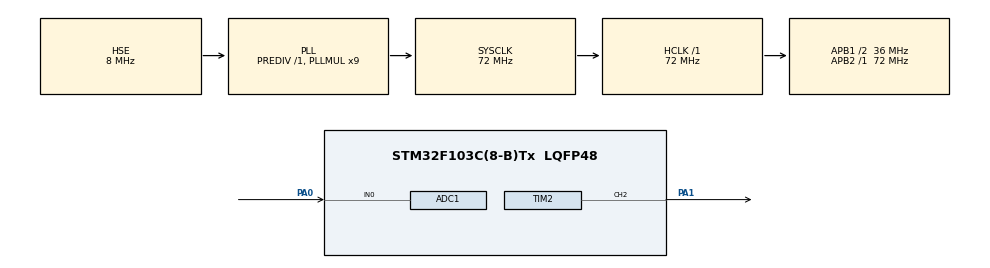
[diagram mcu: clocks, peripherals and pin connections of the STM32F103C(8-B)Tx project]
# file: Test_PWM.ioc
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ADC1.Channel-3\#ChannelRegularConversion=ADC_CHANNEL_0
ADC1.ContinuousConvMode=ENABLE
ADC1.NbrOfConversionFlag=1
ADC1.Rank-3\#ChannelRegularConversion=1
ADC1.SamplingTime-3\#ChannelRegularConversion=ADC_SAMPLETIME_1CYCLE_5
ADC1.master=1
FREERTOS.Tasks01=defaultTask,24,128,StartDefaultTask,Default,NULL,Dynamic,NULL,NULL;my_PhotoResisto,8,200,Start_PhotoResistor_Task,Default,NULL,Static,my_PhotoResistoBuffer,my_PhotoResistoControlBlock
Mcu.Family=STM32F1
Mcu.Name=STM32F103C(8-B)Tx
Mcu.Package=LQFP48
NVIC.PriorityGroup=NVIC_PRIORITYGROUP_4
NVIC.TIM4_IRQn=true\:0\:0\:false\:false\:true\:false\:false\:true
NVIC.TimeBase=TIM4_IRQn
NVIC.TimeBaseIP=TIM4
PA0-WKUP.Signal=ADCx_IN0
PA1.Signal=S_TIM2_CH2
PA13.Mode=Trace_Asynchronous_SW
PA13.Signal=SYS_JTMS-SWDIO
PA14.Mode=Trace_Asynchronous_SW
PA14.Signal=SYS_JTCK-SWCLK
PB3.Mode=Trace_Asynchronous_SW
PB3.Signal=SYS_JTDO-TRACESWO
PD0-OSC_IN.Mode=HSE-External-Oscillator
PD0-OSC_IN.Signal=RCC_OSC_IN
PD1-OSC_OUT.Mode=HSE-External-Oscillator
PD1-OSC_OUT.Signal=RCC_OSC_OUT
ProjectManager.HeapSize=0x200
ProjectManager.StackSize=0x400
ProjectManager.TargetToolchain=STM32CubeIDE
RCC.ADCPresc=RCC_ADCPCLK2_DIV6
RCC.AHBFreq_Value=72000000
RCC.APB1CLKDivider=RCC_HCLK_DIV2
RCC.APB1Freq_Value=36000000
RCC.APB1TimFreq_Value=72000000
RCC.APB2Freq_Value=72000000
RCC.APB2TimFreq_Value=72000000
RCC.HCLKFreq_Value=72000000
RCC.PLLMUL=RCC_PLL_MUL9
RCC.PLLSourceVirtual=RCC_PLLSOURCE_HSE
RCC.SYSCLKFreq_VALUE=72000000
RCC.SYSCLKSource=RCC_SYSCLKSOURCE_PLLCLK
RCC.USBFreq_Value=72000000
SH.ADCx_IN0.0=ADC1_IN0,IN0
SH.S_TIM2_CH2.0=TIM2_CH2,PWM Generation2 CH2
TIM2.Channel-PWM\ Generation2\ CH2=TIM_CHANNEL_2
TIM2.Pulse-PWM\ Generation2\ CH2=32767
VP_FREERTOS_VS_CMSIS_V2.Mode=CMSIS_V2
VP_SYS_VS_tim4.Mode=TIM4
VP_TIM2_VS_ClockSourceINT.Mode=Internal
board=custom

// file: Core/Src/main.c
/* USER CODE BEGIN Header */
/**
 ******************************************************************************
 * @file           : main.c
 * @brief          : Main program body
 ******************************************************************************
 * @attention
 *
 * <h2><center>&copy; Copyright (c) 2021 STMicroelectronics.
 * All rights reserved.</center></h2>
 *
 * This software component is licensed by ST under Ultimate Liberty license
 * SLA0044, the "License"; You may not use this file except in compliance with
 * the License. You may obtain a copy of the License at:
 *                             www.st.com/SLA0044
 *
 ******************************************************************************
 */
/* USER CODE END Header */
#include "main.h"
#include "cmsis_os.h"

/* USER CODE BEGIN Includes */
#include <stdio.h> /* пїЅпїЅпїЅ printf */
#include "stdbool.h"
unsigned long T; // For PWM
uint8_t i = 0;   // For PWM
bool flag;       // For PWM
uint16_t adc_value; // For ADC
int16_t value = 0; // For function "map"
/* USER CODE END Includes */

typedef StaticTask_t osStaticThreadDef_t;

ADC_HandleTypeDef hadc1;

TIM_HandleTypeDef htim2;

/* Definitions for defaultTask */
osThreadId_t defaultTaskHandle;
const osThreadAttr_t defaultTask_attributes = { .name = "defaultTask",
		.priority = (osPriority_t) osPriorityNormal, .stack_size = 128 * 4 };
/* Definitions for my_PhotoResisto */
osThreadId_t my_PhotoResistoHandle;
uint32_t my_PhotoResistoBuffer[200];
osStaticThreadDef_t my_PhotoResistoControlBlock;
const osThreadAttr_t my_PhotoResisto_attributes = { .name = "my_PhotoResisto",
		.stack_mem = &my_PhotoResistoBuffer[0], .stack_size =
				sizeof(my_PhotoResistoBuffer), .cb_mem =
				&my_PhotoResistoControlBlock, .cb_size =
				sizeof(my_PhotoResistoControlBlock), .priority =
				(osPriority_t) osPriorityLow, };

void SystemClock_Config(void);
static void MX_GPIO_Init(void);
static void MX_TIM2_Init(void);
static void MX_ADC1_Init(void);
void StartDefaultTask(void *argument);
void Start_PhotoResistor_Task(void *argument);

/* USER CODE BEGIN 0 */
/*-----------------------------for prinf--------------------------------------*/
int _write(int file, uint8_t *ptr, int len) {
	for (int DataIdx = 0; DataIdx < len; DataIdx++) {
		ITM_SendChar(*ptr++);
	}
	return len;
}
/*-----------------------------End prinf--------------------------------------*/
/* USER CODE END 0 */

int main(void) {

	/* MCU Configuration--------------------------------------------------------*/

	/* Reset of all peripherals, Initializes the Flash interface and the Systick. */
	HAL_Init();

	/* Configure the system clock */
	SystemClock_Config();

	/* Initialize all configured peripherals */
	MX_GPIO_Init();
	MX_TIM2_Init();
	MX_ADC1_Init();
	/* USER CODE BEGIN 2 */
	HAL_TIM_PWM_Start(&htim2, TIM_CHANNEL_2); // Запускаем ШИМ на TIM2 на канале 2.
	HAL_ADC_Start(&hadc1); // Запустили АЦП
	HAL_ADCEx_Calibration_Start(&hadc1); // Делаем калибровку ADC
	/* USER CODE END 2 */

	/* Init scheduler */
	osKernelInitialize();

	/* Create the thread(s) */
	/* creation of defaultTask */
	defaultTaskHandle = osThreadNew(StartDefaultTask, NULL,
			&defaultTask_attributes);

	/* creation of my_PhotoResisto */
	my_PhotoResistoHandle = osThreadNew(Start_PhotoResistor_Task, NULL,
			&my_PhotoResisto_attributes);

	/* Start scheduler */
	osKernelStart();

	/* We should never get here as control is now taken by the scheduler */
	/* Infinite loop */
	while (1) {

	}
}

void SystemClock_Config(void) {
	RCC_OscInitTypeDef RCC_OscInitStruct = { 0 };
	RCC_ClkInitTypeDef RCC_ClkInitStruct = { 0 };
	RCC_PeriphCLKInitTypeDef PeriphClkInit = { 0 };

	/** Initializes the RCC Oscillators according to the specified parameters
	 * in the RCC_OscInitTypeDef structure.
	 */
	RCC_OscInitStruct.OscillatorType = RCC_OSCILLATORTYPE_HSE;
	RCC_OscInitStruct.HSEState = RCC_HSE_ON;
	RCC_OscInitStruct.HSEPredivValue = RCC_HSE_PREDIV_DIV1;
	RCC_OscInitStruct.HSIState = RCC_HSI_ON;
	RCC_OscInitStruct.PLL.PLLState = RCC_PLL_ON;
	RCC_OscInitStruct.PLL.PLLSource = RCC_PLLSOURCE_HSE;
	RCC_OscInitStruct.PLL.PLLMUL = RCC_PLL_MUL9;
	if (HAL_RCC_OscConfig(&RCC_OscInitStruct) != HAL_OK) {
		Error_Handler();
	}
	/** Initializes the CPU, AHB and APB buses clocks
	 */
	RCC_ClkInitStruct.ClockType = RCC_CLOCKTYPE_HCLK | RCC_CLOCKTYPE_SYSCLK
			| RCC_CLOCKTYPE_PCLK1 | RCC_CLOCKTYPE_PCLK2;
	RCC_ClkInitStruct.SYSCLKSource = RCC_SYSCLKSOURCE_PLLCLK;
	RCC_ClkInitStruct.AHBCLKDivider = RCC_SYSCLK_DIV1;
	RCC_ClkInitStruct.APB1CLKDivider = RCC_HCLK_DIV2;
	RCC_ClkInitStruct.APB2CLKDivider = RCC_HCLK_DIV1;

	if (HAL_RCC_ClockConfig(&RCC_ClkInitStruct, FLASH_LATENCY_2) != HAL_OK) {
		Error_Handler();
	}
	PeriphClkInit.PeriphClockSelection = RCC_PERIPHCLK_ADC;
	PeriphClkInit.AdcClockSelection = RCC_ADCPCLK2_DIV6;
	if (HAL_RCCEx_PeriphCLKConfig(&PeriphClkInit) != HAL_OK) {
		Error_Handler();
	}
}

static void MX_ADC1_Init(void) {

	ADC_ChannelConfTypeDef sConfig = { 0 };

	/** Common config
	 */
	hadc1.Instance = ADC1;
	hadc1.Init.ScanConvMode = ADC_SCAN_DISABLE;
	hadc1.Init.ContinuousConvMode = ENABLE;
	hadc1.Init.DiscontinuousConvMode = DISABLE;
	hadc1.Init.ExternalTrigConv = ADC_SOFTWARE_START;
	hadc1.Init.DataAlign = ADC_DATAALIGN_RIGHT;
	hadc1.Init.NbrOfConversion = 1;
	if (HAL_ADC_Init(&hadc1) != HAL_OK) {
		Error_Handler();
	}
	/** Configure Regular Channel
	 */
	sConfig.Channel = ADC_CHANNEL_0;
	sConfig.Rank = ADC_REGULAR_RANK_1;
	sConfig.SamplingTime = ADC_SAMPLETIME_1CYCLE_5;
	if (HAL_ADC_ConfigChannel(&hadc1, &sConfig) != HAL_OK) {
		Error_Handler();
	}

}

static void MX_TIM2_Init(void) {

	TIM_ClockConfigTypeDef sClockSourceConfig = { 0 };
	TIM_MasterConfigTypeDef sMasterConfig = { 0 };
	TIM_OC_InitTypeDef sConfigOC = { 0 };

	htim2.Instance = TIM2;
	htim2.Init.Prescaler = 0;
	htim2.Init.CounterMode = TIM_COUNTERMODE_UP;
	htim2.Init.Period = 255;
	htim2.Init.ClockDivision = TIM_CLOCKDIVISION_DIV1;
	htim2.Init.AutoReloadPreload = TIM_AUTORELOAD_PRELOAD_DISABLE;
	if (HAL_TIM_Base_Init(&htim2) != HAL_OK) {
		Error_Handler();
	}
	sClockSourceConfig.ClockSource = TIM_CLOCKSOURCE_INTERNAL;
	if (HAL_TIM_ConfigClockSource(&htim2, &sClockSourceConfig) != HAL_OK) {
		Error_Handler();
	}
	if (HAL_TIM_PWM_Init(&htim2) != HAL_OK) {
		Error_Handler();
	}
	sMasterConfig.MasterOutputTrigger = TIM_TRGO_RESET;
	sMasterConfig.MasterSlaveMode = TIM_MASTERSLAVEMODE_DISABLE;
	if (HAL_TIMEx_MasterConfigSynchronization(&htim2, &sMasterConfig)
			!= HAL_OK) {
		Error_Handler();
	}
	sConfigOC.OCMode = TIM_OCMODE_PWM1;
	sConfigOC.Pulse = 0;
	sConfigOC.OCPolarity = TIM_OCPOLARITY_HIGH;
	sConfigOC.OCFastMode = TIM_OCFAST_DISABLE;
	if (HAL_TIM_PWM_ConfigChannel(&htim2, &sConfigOC, TIM_CHANNEL_2)
			!= HAL_OK) {
		Error_Handler();
	}
	HAL_TIM_MspPostInit(&htim2);

}

static void MX_GPIO_Init(void) {

	/* GPIO Ports Clock Enable */
	__HAL_RCC_GPIOD_CLK_ENABLE();
	__HAL_RCC_GPIOA_CLK_ENABLE();
	__HAL_RCC_GPIOB_CLK_ENABLE();

}

void StartDefaultTask(void *argument) {
	for (;;) {
		osDelay(1);
	}
}

void Start_PhotoResistor_Task(void *argument) {
	/* USER CODE BEGIN Start_PhotoResistor_Task */
	/* Infinite loop */
	for (;;) {
		/*		if (HAL_GetTick() - T >= 5) {  // "Припровняли" тики к секундам
		 T = HAL_GetTick();
		 if (flag) {
		 TIM2->CCR2 = i;
		 TIM2->CCR3 = 255 - i;
		 i++;
		 if (i == 255) {
		 i = 0;
		 flag = 0;
		 }
		 }
		 if (!flag) {
		 TIM2->CCR3 = i;
		 TIM2->CCR2 = 255 - i;
		 i++;
		 if (i == 255) {
		 i = 0;
		 flag = 1;
		 }
		 }
		 }*/

		/*---------------------------------------*/
		HAL_ADC_Start(&hadc1); // Запускаем проеобразование сигнала с АЦП1
		HAL_ADC_PollForConversion(&hadc1, 100); // Ожидание окончания преобразования! 100мс -это не означает что он будет ждать 100мс! Если преобразуется раньше то и ...
		adc_value = HAL_ADC_GetValue(&hadc1); // Читаем наше значение с АЦП1.
		printf("adc_value - %d \n", adc_value);
		HAL_ADC_Stop(&hadc1); // Останавливаем проеобразование сигнала с АЦП1
		int16_t in_max = 2000; // было 4095
		int8_t in_min = 200;  // было 0
		unsigned char out_max = 255;
		int8_t out_min = 0;

		value = (adc_value - in_min) * (out_max - out_min) / (in_max - in_min)
				+ out_min; // Function map
		if (value >= 255) {
			value = 255;
		}
		if (value <= 0) {
			value = 0;
		}
		value = 255 - value; // Инвертируем значение.
		TIM2->CCR2 = value; // analogWrite(PWM,value);

	}
	/* USER CODE END Start_PhotoResistor_Task */
}

void HAL_TIM_PeriodElapsedCallback(TIM_HandleTypeDef *htim) {
	if (htim->Instance == TIM4) {
		HAL_IncTick();
	}
}

void Error_Handler(void) {
	__disable_irq();
	while (1) {
	}
}

/************************ (C) COPYRIGHT STMicroelectronics *****END OF FILE****/
